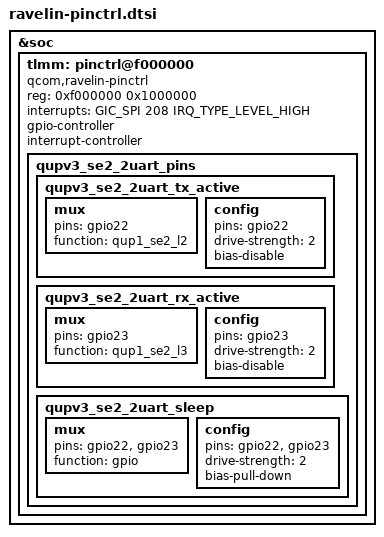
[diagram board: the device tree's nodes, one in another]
&soc {
	tlmm: pinctrl@f000000 {
		compatible = "qcom,ravelin-pinctrl";
		reg = <0xf000000 0x1000000>;
		interrupts = <GIC_SPI 208 IRQ_TYPE_LEVEL_HIGH>;
		gpio-controller;
		#gpio-cells = <2>;
		interrupt-controller;
		#interrupt-cells = <2>;

		qupv3_se2_2uart_pins: qupv3_se2_2uart_pins {
			qupv3_se2_2uart_tx_active: qupv3_se2_2uart_tx_active {
				mux {
					pins = "gpio22";
					function = "qup1_se2_l2";
				};

				config {
					pins = "gpio22";
					drive-strength = <2>;
					bias-disable;
				};
			};

			qupv3_se2_2uart_rx_active: qupv3_se2_2uart_rx_active {
				mux {
					pins = "gpio23";
					function = "qup1_se2_l3";
				};

				config {
					pins = "gpio23";
					drive-strength = <2>;
					bias-disable;
				};
			};

			qupv3_se2_2uart_sleep: qupv3_se2_2uart_sleep {
				mux {
					pins = "gpio22", "gpio23";
					function = "gpio";
				};

				config {
					pins = "gpio22", "gpio23";
					drive-strength = <2>;
					bias-pull-down;
				};
			};
		};
	};
};
